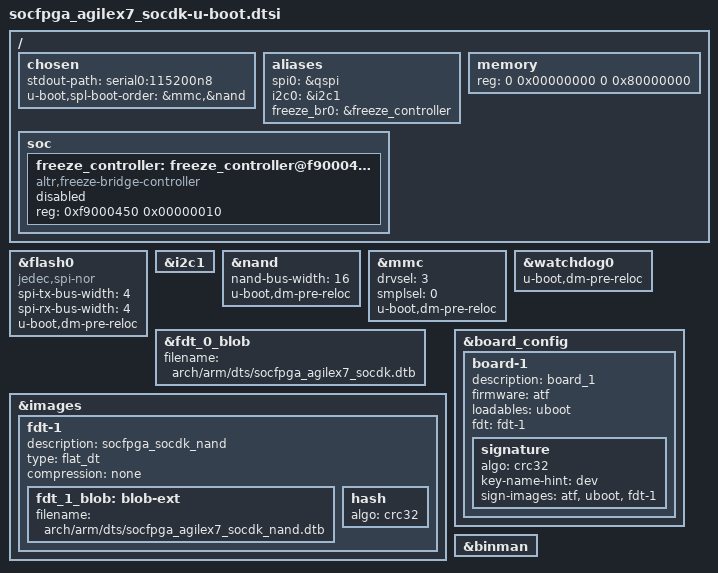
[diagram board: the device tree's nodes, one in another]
// SPDX-License-Identifier: GPL-2.0+
/*
 * U-Boot additions
 *
 * Copyright (C) 2023 Intel Corporation <www.intel.com>
 */

#include "socfpga_agilex7-u-boot.dtsi"

/{
	chosen {
		stdout-path = "serial0:115200n8";
		u-boot,spl-boot-order = &mmc,&nand;
	};

	aliases {
		spi0 = &qspi;
		i2c0 = &i2c1;
		freeze_br0 = &freeze_controller;
	};

	soc {
		freeze_controller: freeze_controller@f9000450 {
			compatible = "altr,freeze-bridge-controller";
			reg = <0xf9000450 0x00000010>;
			status = "disabled";
		};
	};

	memory {
		/* 2GB */
		reg = <0 0x00000000 0 0x80000000>;
	};
};

&flash0 {
	compatible = "jedec,spi-nor";
	spi-tx-bus-width = <4>;
	spi-rx-bus-width = <4>;
	u-boot,dm-pre-reloc;
	/delete-property/ cdns,read-delay;
};

&i2c1 {
	status = "okay";
};

&nand {
	status = "okay";
	nand-bus-width = <16>;
	u-boot,dm-pre-reloc;
};

&mmc {
	drvsel = <3>;
	smplsel = <0>;
	u-boot,dm-pre-reloc;
};

&watchdog0 {
	u-boot,dm-pre-reloc;
};

#if !defined(CONFIG_SOCFPGA_SECURE_VAB_AUTH)
&fdt_0_blob {
	filename = "arch/arm/dts/socfpga_agilex7_socdk.dtb";
};

&images {
	fdt-1 {
		description = "socfpga_socdk_nand";
		type = "flat_dt";
		compression = "none";
		fdt_1_blob: blob-ext {
			filename = "arch/arm/dts/socfpga_agilex7_socdk_nand.dtb";
		};
		hash {
			algo = "crc32";
		};
	};
};

&board_config {
	board-1 {
		description = "board_1";
		firmware = "atf";
		loadables = "uboot";
		fdt = "fdt-1";
		signature {
			algo = "crc32";
			key-name-hint = "dev";
			sign-images = "atf", "uboot", "fdt-1";
		};
	};
};

&binman {
	/delete-node/ kernel;
};
#endif

